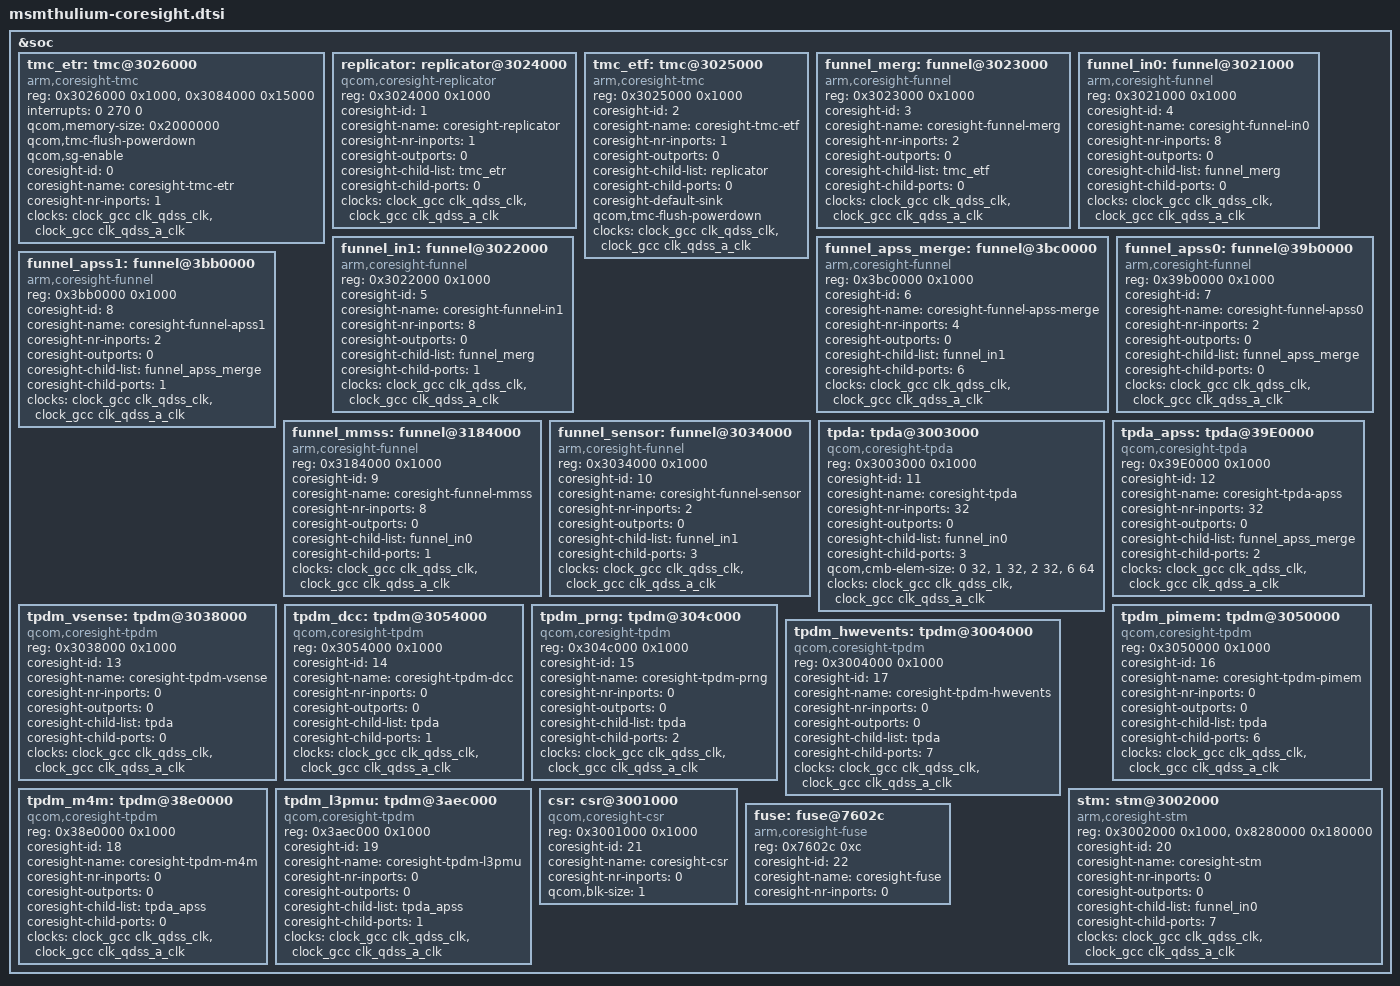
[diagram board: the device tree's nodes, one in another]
/* Copyright (c) 2014-2015, The Linux Foundation. All rights reserved.
 *
 * This program is free software; you can redistribute it and/or modify
 * it under the terms of the GNU General Public License version 2 and
 * only version 2 as published by the Free Software Foundation.
 *
 * This program is distributed in the hope that it will be useful,
 * but WITHOUT ANY WARRANTY; without even the implied warranty of
 * MERCHANTABILITY or FITNESS FOR A PARTICULAR PURPOSE.  See the
 * GNU General Public License for more details.
 */

&soc {
	tmc_etr: tmc@3026000 {
		compatible = "arm,coresight-tmc";
		reg = <0x3026000 0x1000>,
		      <0x3084000 0x15000>;
		reg-names = "tmc-base", "bam-base";
		interrupts = <0 270 0>;
		interrupt-names = "byte-cntr-irq";

		qcom,memory-size = <0x2000000>;
		qcom,tmc-flush-powerdown;
		qcom,sg-enable;

		coresight-id = <0>;
		coresight-name = "coresight-tmc-etr";
		coresight-nr-inports = <1>;

		clocks = <&clock_gcc clk_qdss_clk>,
			 <&clock_gcc clk_qdss_a_clk>;
		clock-names = "core_clk", "core_a_clk";
	};

	replicator: replicator@3024000 {
		compatible = "qcom,coresight-replicator";
		reg = <0x3024000 0x1000>;
		reg-names = "replicator-base";

		coresight-id = <1>;
		coresight-name = "coresight-replicator";
		coresight-nr-inports = <1>;
		coresight-outports = <0>;
		coresight-child-list = <&tmc_etr>;
		coresight-child-ports = <0>;

		clocks = <&clock_gcc clk_qdss_clk>,
			 <&clock_gcc clk_qdss_a_clk>;
		clock-names = "core_clk", "core_a_clk";
	};

	tmc_etf: tmc@3025000 {
		compatible = "arm,coresight-tmc";
		reg = <0x3025000 0x1000>;
		reg-names = "tmc-base";

		coresight-id = <2>;
		coresight-name = "coresight-tmc-etf";
		coresight-nr-inports = <1>;
		coresight-outports = <0>;
		coresight-child-list = <&replicator>;
		coresight-child-ports = <0>;
		coresight-default-sink;

		qcom,tmc-flush-powerdown;

		clocks = <&clock_gcc clk_qdss_clk>,
			 <&clock_gcc clk_qdss_a_clk>;
		clock-names = "core_clk", "core_a_clk";
	};

	funnel_merg: funnel@3023000 {
		compatible = "arm,coresight-funnel";
		reg = <0x3023000 0x1000>;
		reg-names = "funnel-base";

		coresight-id = <3>;
		coresight-name = "coresight-funnel-merg";
		coresight-nr-inports = <2>;
		coresight-outports = <0>;
		coresight-child-list = <&tmc_etf>;
		coresight-child-ports = <0>;

		clocks = <&clock_gcc clk_qdss_clk>,
			 <&clock_gcc clk_qdss_a_clk>;
		clock-names = "core_clk", "core_a_clk";
	};

	funnel_in0: funnel@3021000 {
		compatible = "arm,coresight-funnel";
		reg = <0x3021000 0x1000>;
		reg-names = "funnel-base";

		coresight-id = <4>;
		coresight-name = "coresight-funnel-in0";
		coresight-nr-inports = <8>;
		coresight-outports = <0>;
		coresight-child-list = <&funnel_merg>;
		coresight-child-ports = <0>;

		clocks = <&clock_gcc clk_qdss_clk>,
			 <&clock_gcc clk_qdss_a_clk>;
		clock-names = "core_clk", "core_a_clk";
	};

	funnel_in1: funnel@3022000 {
		compatible = "arm,coresight-funnel";
		reg = <0x3022000 0x1000>;
		reg-names = "funnel-base";

		coresight-id = <5>;
		coresight-name = "coresight-funnel-in1";
		coresight-nr-inports = <8>;
		coresight-outports = <0>;
		coresight-child-list = <&funnel_merg>;
		coresight-child-ports = <1>;

		clocks = <&clock_gcc clk_qdss_clk>,
			 <&clock_gcc clk_qdss_a_clk>;
		clock-names = "core_clk", "core_a_clk";
	};

	funnel_apss_merge: funnel@3bc0000 {
		compatible = "arm,coresight-funnel";
		reg = <0x3bc0000 0x1000>;
		reg-names = "funnel-base";

		coresight-id = <6>;
		coresight-name = "coresight-funnel-apss-merge";
		coresight-nr-inports = <4>;
		coresight-outports = <0>;
		coresight-child-list = <&funnel_in1>;
		coresight-child-ports = <6>;

		clocks = <&clock_gcc clk_qdss_clk>,
			 <&clock_gcc clk_qdss_a_clk>;
		clock-names = "core_clk", "core_a_clk";
	};

	funnel_apss0: funnel@39b0000 {
		compatible = "arm,coresight-funnel";
		reg = <0x39b0000 0x1000>;
		reg-names = "funnel-base";

		coresight-id = <7>;
		coresight-name = "coresight-funnel-apss0";
		coresight-nr-inports = <2>;
		coresight-outports = <0>;
		coresight-child-list = <&funnel_apss_merge>;
		coresight-child-ports = <0>;

		clocks = <&clock_gcc clk_qdss_clk>,
			 <&clock_gcc clk_qdss_a_clk>;
		clock-names = "core_clk", "core_a_clk";
	};

	funnel_apss1: funnel@3bb0000 {
		compatible = "arm,coresight-funnel";
		reg = <0x3bb0000 0x1000>;
		reg-names = "funnel-base";

		coresight-id = <8>;
		coresight-name = "coresight-funnel-apss1";
		coresight-nr-inports = <2>;
		coresight-outports = <0>;
		coresight-child-list = <&funnel_apss_merge>;
		coresight-child-ports = <1>;

		clocks = <&clock_gcc clk_qdss_clk>,
			 <&clock_gcc clk_qdss_a_clk>;
		clock-names = "core_clk", "core_a_clk";
	};

	funnel_mmss: funnel@3184000 {
		compatible = "arm,coresight-funnel";
		reg = <0x3184000 0x1000>;
		reg-names = "funnel-base";

		coresight-id = <9>;
		coresight-name = "coresight-funnel-mmss";
		coresight-nr-inports = <8>;
		coresight-outports = <0>;
		coresight-child-list = <&funnel_in0>;
		coresight-child-ports = <1>;

		clocks = <&clock_gcc clk_qdss_clk>,
			 <&clock_gcc clk_qdss_a_clk>;
		clock-names = "core_clk", "core_a_clk";
	};

	funnel_sensor: funnel@3034000 {
		compatible = "arm,coresight-funnel";
		reg = <0x3034000 0x1000>;
		reg-names = "funnel-base";

		coresight-id = <10>;
		coresight-name = "coresight-funnel-sensor";
		coresight-nr-inports = <2>;
		coresight-outports = <0>;
		coresight-child-list = <&funnel_in1>;
		coresight-child-ports = <3>;

		clocks = <&clock_gcc clk_qdss_clk>,
			 <&clock_gcc clk_qdss_a_clk>;
		clock-names = "core_clk", "core_a_clk";
	};

	tpda: tpda@3003000 {
		compatible = "qcom,coresight-tpda";
		reg = <0x3003000 0x1000>;
		reg-names = "tpda-base";

		coresight-id = <11>;
		coresight-name = "coresight-tpda";
		coresight-nr-inports = <32>;
		coresight-outports = <0>;
		coresight-child-list = <&funnel_in0>;
		coresight-child-ports = <3>;

		qcom,cmb-elem-size = <0 32>,
				     <1 32>,
				     <2 32>,
				     <6 64>;

		clocks = <&clock_gcc clk_qdss_clk>,
			 <&clock_gcc clk_qdss_a_clk>;
		clock-names = "core_clk", "core_a_clk";
	};

	tpda_apss: tpda@39E0000 {
		compatible = "qcom,coresight-tpda";
		reg = <0x39E0000 0x1000>;
		reg-names = "tpda-base";

		coresight-id = <12>;
		coresight-name = "coresight-tpda-apss";
		coresight-nr-inports = <32>;
		coresight-outports = <0>;
		coresight-child-list = <&funnel_apss_merge>;
		coresight-child-ports = <2>;

		clocks = <&clock_gcc clk_qdss_clk>,
			 <&clock_gcc clk_qdss_a_clk>;
		clock-names = "core_clk", "core_a_clk";
	};

	tpdm_vsense: tpdm@3038000 {
		compatible = "qcom,coresight-tpdm";
		reg = <0x3038000 0x1000>;
		reg-names = "tpdm-base";

		coresight-id = <13>;
		coresight-name = "coresight-tpdm-vsense";
		coresight-nr-inports = <0>;
		coresight-outports = <0>;
		coresight-child-list = <&tpda>;
		coresight-child-ports = <0>;

		clocks = <&clock_gcc clk_qdss_clk>,
			 <&clock_gcc clk_qdss_a_clk>;
		clock-names = "core_clk", "core_a_clk";
	};

	tpdm_dcc: tpdm@3054000 {
		compatible = "qcom,coresight-tpdm";
		reg = <0x3054000 0x1000>;
		reg-names = "tpdm-base";

		coresight-id = <14>;
		coresight-name = "coresight-tpdm-dcc";
		coresight-nr-inports = <0>;
		coresight-outports = <0>;
		coresight-child-list = <&tpda>;
		coresight-child-ports = <1>;

		clocks = <&clock_gcc clk_qdss_clk>,
			 <&clock_gcc clk_qdss_a_clk>;
		clock-names = "core_clk", "core_a_clk";
	};

	tpdm_prng: tpdm@304c000 {
		compatible = "qcom,coresight-tpdm";
		reg = <0x304c000 0x1000>;
		reg-names = "tpdm-base";

		coresight-id = <15>;
		coresight-name = "coresight-tpdm-prng";
		coresight-nr-inports = <0>;
		coresight-outports = <0>;
		coresight-child-list = <&tpda>;
		coresight-child-ports = <2>;

		clocks = <&clock_gcc clk_qdss_clk>,
			 <&clock_gcc clk_qdss_a_clk>;
		clock-names = "core_clk", "core_a_clk";
	};

	tpdm_pimem: tpdm@3050000 {
		compatible = "qcom,coresight-tpdm";
		reg = <0x3050000 0x1000>;
		reg-names = "tpdm-base";

		coresight-id = <16>;
		coresight-name = "coresight-tpdm-pimem";
		coresight-nr-inports = <0>;
		coresight-outports = <0>;
		coresight-child-list = <&tpda>;
		coresight-child-ports = <6>;

		clocks = <&clock_gcc clk_qdss_clk>,
			 <&clock_gcc clk_qdss_a_clk>;
		clock-names = "core_clk", "core_a_clk";
	};

	tpdm_hwevents: tpdm@3004000 {
		compatible = "qcom,coresight-tpdm";
		reg = <0x3004000 0x1000>;
		reg-names = "tpdm-base";

		coresight-id = <17>;
		coresight-name = "coresight-tpdm-hwevents";
		coresight-nr-inports = <0>;
		coresight-outports = <0>;
		coresight-child-list = <&tpda>;
		coresight-child-ports = <7>;

		clocks = <&clock_gcc clk_qdss_clk>,
			 <&clock_gcc clk_qdss_a_clk>;
		clock-names = "core_clk", "core_a_clk";
	};

	tpdm_m4m: tpdm@38e0000 {
		compatible = "qcom,coresight-tpdm";
		reg = <0x38e0000 0x1000>;
		reg-names = "tpdm-base";

		coresight-id = <18>;
		coresight-name = "coresight-tpdm-m4m";
		coresight-nr-inports = <0>;
		coresight-outports = <0>;
		coresight-child-list = <&tpda_apss>;
		coresight-child-ports = <0>;

		clocks = <&clock_gcc clk_qdss_clk>,
			 <&clock_gcc clk_qdss_a_clk>;
		clock-names = "core_clk", "core_a_clk";
	};

	tpdm_l3pmu: tpdm@3aec000 {
		compatible = "qcom,coresight-tpdm";
		reg = <0x3aec000 0x1000>;
		reg-names = "tpdm-base";

		coresight-id = <19>;
		coresight-name = "coresight-tpdm-l3pmu";
		coresight-nr-inports = <0>;
		coresight-outports = <0>;
		coresight-child-list = <&tpda_apss>;
		coresight-child-ports = <1>;

		clocks = <&clock_gcc clk_qdss_clk>,
			 <&clock_gcc clk_qdss_a_clk>;
		clock-names = "core_clk", "core_a_clk";
	};

	stm: stm@3002000 {
		compatible = "arm,coresight-stm";
		reg = <0x3002000 0x1000>,
		      <0x8280000 0x180000>;
		reg-names = "stm-base", "stm-data-base";

		coresight-id = <20>;
		coresight-name = "coresight-stm";
		coresight-nr-inports = <0>;
		coresight-outports = <0>;
		coresight-child-list = <&funnel_in0>;
		coresight-child-ports = <7>;

		clocks = <&clock_gcc clk_qdss_clk>,
			 <&clock_gcc clk_qdss_a_clk>;
		clock-names = "core_clk", "core_a_clk";
	};

	csr: csr@3001000 {
		compatible = "qcom,coresight-csr";
		reg = <0x3001000 0x1000>;
		reg-names = "csr-base";

		coresight-id = <21>;
		coresight-name = "coresight-csr";
		coresight-nr-inports = <0>;

		qcom,blk-size = <1>;
	};

	fuse: fuse@7602c {
		compatible = "arm,coresight-fuse";
		reg = <0x7602c 0xc>;
		reg-names = "fuse-base";

		coresight-id = <22>;
		coresight-name = "coresight-fuse";
		coresight-nr-inports = <0>;
	};
};
